# MM32F013x register map
File version: 1.01
CPU: CM0 r0p0, little endian, no MPU, no FPU, 2 interrupt priority bits
Registers are 32-bit, read-write, reset 0x0 unless marked. A register's access mark holds for its fields unless they carry their own. Offsets are from the block's base; [hi:lo] are bit positions.

## UART1 — Universal asynchronous receiver transmitter
Base 0x40013800
Same registers: UART2 0x40004400
0x00 TDR — Transmit data register
  [7:0] TXREG
0x04 RDR ro — Receive data register
  [7:0] RXREG
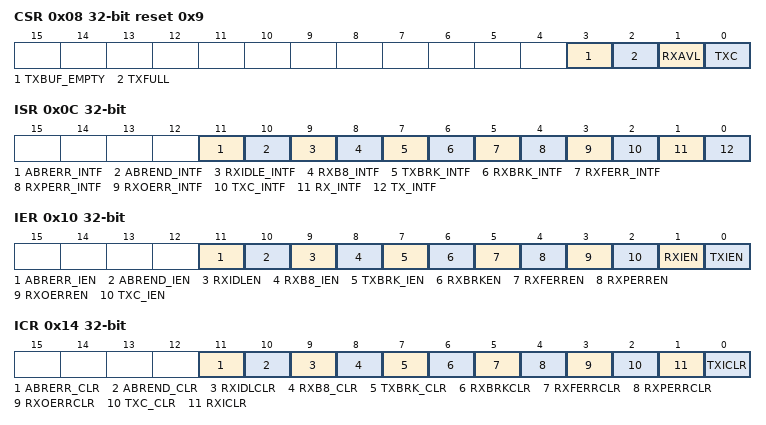
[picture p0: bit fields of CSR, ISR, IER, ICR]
0x08 CSR ro reset 0x9 — Current status register
  [3] TXBUF_EMPTY — Transmit buffer empty flag bit
  [2] TXFULL — Transmit buffer full flag bit
  [1] RXAVL — Receive valid data flag bit
  [0] TXC — Transmit complete flag bit
0x0C ISR ro — Interrupt status register
  [11] ABRERR_INTF — Automatic baud rate error interrupt flag bit
  [10] ABREND_INTF — Automatic baud rate end interrupt flag bit
  [9] RXIDLE_INTF — Receive frame idle interrupt flag bit
  [8] RXB8_INTF — Receive Bit 8 Interrupt Flag Bit
  [7] TXBRK_INTF — Transmit Break Frame Interrupt Flag Bit
  [6] RXBRK_INTF — Receive frame break interrupt flag bit
  [5] RXFERR_INTF — Frame error interrupt flag bit
  [4] RXPERR_INTF — Parity error interrupt flag bit
  [3] RXOERR_INTF — Receive overflow error interrupt flag bit
  [2] TXC_INTF — UART Transmit Complete Interrupt Flag bit
  [1] RX_INTF — Receive valid data interrupt flag bit
  [0] TX_INTF — Transmit buffer empty interrupt flag bit
0x10 IER — Interrupt enable register
  [11] ABRERR_IEN — Automatic baud rate error interrupt enable
  [10] ABREND_IEN — Automatic baud rate end interrupt enable
  [9] RXIDLEN — Receive frame idle interrupt enable bit
  [8] RXB8_IEN — Receive Bit 8 Interrupt Enable Bit
  [7] TXBRK_IEN — Transmit Break Frame Interrupt Enable Bit
  [6] RXBRKEN — Receive frame break interrupt enable bit
  [5] RXFERREN — Frame error interrupt enable bit
  [4] RXPERREN — Parity error interrupt enable bit
  [3] RXOERREN — Receive overflow error interrupt enable bit
  [2] TXC_IEN — Transmit complete interrupt enable bit
  [1] RXIEN — Receive buffer interrupt enable bit
  [0] TXIEN — Transmit buffer empty interrupt enable bit
0x14 ICR wo — Interrupt Clear Register
  [11] ABRERR_CLR — Auto baud rate error interrupt clear bit
  [10] ABREND_CLR — Auto baud rate end interrupt clear bit
  [9] RXIDLCLR — Receive Bit 8 Interrupt clear Bit
  [8] RXB8_CLR — Receive Bit 8 Interrupt clear Bit
  [7] TXBRK_CLR — Transmit Break Frame Interrupt clear Bit
  [6] RXBRKCLR — Receive frame break interrupt clear bit
  [5] RXFERRCLR — Frame error interrupt clear bit
  [4] RXPERRCLR — Parity error interrupt clear bit
  [3] RXOERRCLR — Receive overflow error interrupt clear bit
  [2] TXC_CLR — Transmit complete interrupt clear bit
  [1] RXICLR — Receive interrupt clear bit
  [0] TXICLR — Transmit buffer empty interrupt clear bit
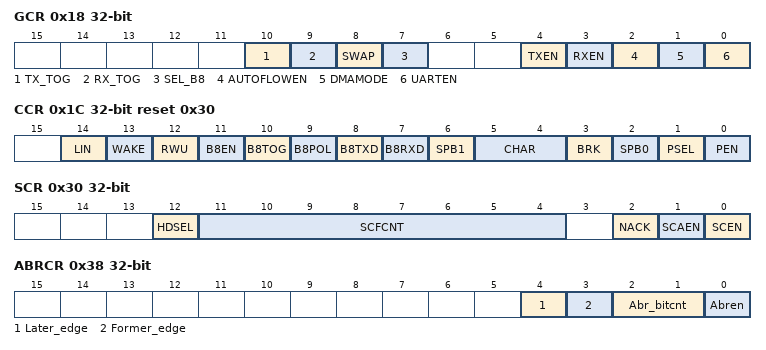
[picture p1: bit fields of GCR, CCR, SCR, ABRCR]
0x18 GCR — Global control register
  [10] TX_TOG — Toggle TX
  [9] RX_TOG — Toggle RX
  [8] SWAP — change swap
  [7] SEL_B8 — Select bit8
  [4] TXEN — Enable transmit
  [3] RXEN — Enable receive
  [2] AUTOFLOWEN — Automatic flow control enable bit
  [1] DMAMODE — DMA mode selection bit
  [0] UARTEN — UART mode selection bit
0x1C CCR reset 0x30 — common control register
  [14] LIN — UART LIN enable bit
  [13] WAKE — Wake up method
  [12] RWU — Receive wake up method
  [11] B8EN — Synchronous frame enable bit
  [10] B8TOG — Synchronous frame auto toggle bit
  [9] B8POL — Synchronous frame polarity control bit
  [8] B8TXD — Synchronous frame transmit
  [7] B8RXD — Synchronous frame receive
  [6] SPB1 — Stop bit 1 selection bit
  [5:4] CHAR — UART width bit
  [3] BRK — UART transmit frame break
  [2] SPB0 — Stop bit 0 selection
  [1] PSEL — Parity selection bit
  [0] PEN — Parity enable bit
0x20 BRR reset 0x1 — Baud rate register
  [15:0] DIV_MANTISSA — Mantissa part of UARTDIV
0x24 FRA — Fractional baud rate register
  [3:0] DIV_Fraction — Fractional part of UARTDIV
0x28 RXADDR — Receive Address Register
  [7:0] RXADDR — Synchronous frame match address
0x2C RXMASK reset 0xFF — Receive Mask Registe
  [7:0] RXMASK — Synchronous frame match address mask
0x30 SCR — Slave Control Register
  [12] HDSEL — Single-wire half-duplex mode selection bit
  [11:4] SCFCNT — ISO7816 protection counter bit
  [2] NACK — Master receive frame answer bit
  [1] SCAEN — ISO7816 check auto-response bit
  [0] SCEN — ISO7816 enable control bit
0x34 IDLR reset 0xC — Data length register
  [15:0] IDLR — Idle data length register
0x38 ABRCR — Automatic Baud Rate Register
  [4] Later_edge — Automatic baud rate after edge selection
  [3] Former_edge — Auto baud rate previous edge selection
  [2:1] Abr_bitcnt — Automatic baud rate detection length
  [0] Abren — Automatic baud rate enable
